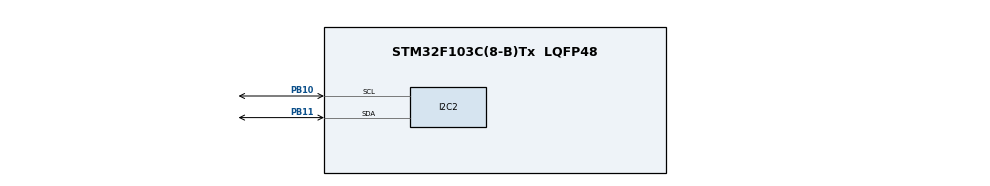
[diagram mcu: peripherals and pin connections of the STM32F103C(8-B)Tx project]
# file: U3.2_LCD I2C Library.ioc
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Mcu.Family=STM32F1
Mcu.Name=STM32F103C(8-B)Tx
Mcu.Package=LQFP48
NVIC.PriorityGroup=NVIC_PRIORITYGROUP_4
PA13.Mode=Serial_Wire
PA13.Signal=SYS_JTMS-SWDIO
PA14.Mode=Serial_Wire
PA14.Signal=SYS_JTCK-SWCLK
PB10.Mode=I2C
PB10.Signal=I2C2_SCL
PB11.Mode=I2C
PB11.Signal=I2C2_SDA
ProjectManager.HeapSize=0x200
ProjectManager.StackSize=0x400
ProjectManager.TargetToolchain=STM32CubeIDE
RCC.APB1Freq_Value=8000000
RCC.APB2Freq_Value=8000000
board=custom

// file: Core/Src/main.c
/* USER CODE BEGIN Header */
/**
  ******************************************************************************
  * @file           : main.c
  * @brief          : Main program body
  ******************************************************************************
  * @attention
  *
  * Copyright (c) 2022 STMicroelectronics.
  * All rights reserved.
  *
  * This software is licensed under terms that can be found in the LICENSE file
  * in the root directory of this software component.
  * If no LICENSE file comes with this software, it is provided AS-IS.
  *
  ******************************************************************************
  */
/* USER CODE END Header */
#include "main.h"

/* USER CODE BEGIN Includes */

#include "LCD_I2C.h"

/* USER CODE END Includes */

 I2C_HandleTypeDef hi2c2;

void SystemClock_Config(void);
static void MX_GPIO_Init(void);
static void MX_I2C2_Init(void);

/* USER CODE BEGIN 0 */
uint8_t arrow_char[] = {
		0b10000,
		0b11000,
		0b11100,
		0b11110,
		0b11100,
		0b11000,
		0b10000,
		0b00000,
};

uint8_t P[] = {
		0b11111,
		0b10001,
		0b10101,
		0b10101,
		0b10001,
		0b10111,
		0b10111,
		0b11111,
};

uint8_t r[] = {
		0b11111,
		0b10001,
		0b10101,
		0b10101,
		0b10001,
		0b10101,
		0b10101,
		0b11111,
};

uint8_t o[] = {
		0b11111,
		0b10001,
		0b10101,
		0b10101,
		0b10101,
		0b10101,
		0b10001,
		0b11111,
};

uint8_t s[] = {
		0b11111,
		0b11111,
		0b11111,
		0b11111,
		0b10001,
		0b11111,
		0b11111,
		0b11111,
};

uint8_t V[] = {
		0b11111,
		0b10101,
		0b10101,
		0b10101,
		0b10101,
		0b10101,
		0b11011,
		0b11111,
};

LCD_I2C_HandleTypeDef hlcd;

/* USER CODE END 0 */

int main(void)
{

  /* MCU Configuration--------------------------------------------------------*/

  /* Reset of all peripherals, Initializes the Flash interface and the Systick. */
  HAL_Init();

  /* Configure the system clock */
  SystemClock_Config();

  /* Initialize all configured peripherals */
  MX_GPIO_Init();
  MX_I2C2_Init();
  /* USER CODE BEGIN 2 */

  LCD_Init(&hlcd, &hi2c2, 20, 4, 0x4E);
  LCD_Backlight(&hlcd);
  HAL_Delay(2000);
//  LCD_Create_Char(&hlcd, 1, arrow_char);
//  LCD_Set_Cursor(&hlcd, 0, 2);
//  LCD_Write_Custom_Char(&hlcd, 1);
//  LCD_Cursor_Blink(&hlcd);

  LCD_Create_Char(&hlcd, 0, P);
  LCD_Set_Cursor(&hlcd, 7, 0);
  LCD_Write_Custom_Char(&hlcd, 0);

  LCD_Create_Char(&hlcd, 1, r);
  LCD_Set_Cursor(&hlcd, 8, 0);
  LCD_Write_Custom_Char(&hlcd, 1);

  LCD_Create_Char(&hlcd, 2, o);
  LCD_Set_Cursor(&hlcd, 9, 0);
  LCD_Write_Custom_Char(&hlcd, 2);

  LCD_Create_Char(&hlcd, 3, s);
  LCD_Set_Cursor(&hlcd, 10, 0);
  LCD_Write_Custom_Char(&hlcd, 3);

  LCD_Create_Char(&hlcd, 4, V);
  LCD_Set_Cursor(&hlcd, 11, 0);
  LCD_Write_Custom_Char(&hlcd, 4);

  LCD_Set_Cursor(&hlcd, 2, 1);
  LCD_Write(&hlcd, "Operator System");

  LCD_Set_Cursor(&hlcd, 5, 2);
  LCD_Write(&hlcd, "Version 1.0");

  HAL_Delay(5000);

  LCD_clear(&hlcd);

  LCD_Set_Cursor(&hlcd, 6, 1);
  LCD_Write(&hlcd, "Welcome!");
  LCD_Set_Cursor(&hlcd, 5, 2);
  LCD_Write(&hlcd, "Loading");

  /* USER CODE END 2 */

  /* Infinite loop */
  while (1)
  {

    /* USER CODE BEGIN 3 */
	  for(int i = 0; i < 3; i++){
		  LCD_Set_Cursor(&hlcd, 12 + i, 2);
		  LCD_Write(&hlcd, ".");
		  HAL_Delay(500);
	  }
	  for(int i = 0; i < 3; i++){
		  LCD_Set_Cursor(&hlcd, 12 + i, 2);
		  LCD_Write(&hlcd, " ");
	  }
	  HAL_Delay(500);

  }
  /* USER CODE END 3 */
}

void SystemClock_Config(void)
{
  RCC_OscInitTypeDef RCC_OscInitStruct = {0};
  RCC_ClkInitTypeDef RCC_ClkInitStruct = {0};

  /** Initializes the RCC Oscillators according to the specified parameters
  * in the RCC_OscInitTypeDef structure.
  */
  RCC_OscInitStruct.OscillatorType = RCC_OSCILLATORTYPE_HSI;
  RCC_OscInitStruct.HSIState = RCC_HSI_ON;
  RCC_OscInitStruct.HSICalibrationValue = RCC_HSICALIBRATION_DEFAULT;
  RCC_OscInitStruct.PLL.PLLState = RCC_PLL_NONE;
  if (HAL_RCC_OscConfig(&RCC_OscInitStruct) != HAL_OK)
  {
    Error_Handler();
  }

  /** Initializes the CPU, AHB and APB buses clocks
  */
  RCC_ClkInitStruct.ClockType = RCC_CLOCKTYPE_HCLK|RCC_CLOCKTYPE_SYSCLK
                              |RCC_CLOCKTYPE_PCLK1|RCC_CLOCKTYPE_PCLK2;
  RCC_ClkInitStruct.SYSCLKSource = RCC_SYSCLKSOURCE_HSI;
  RCC_ClkInitStruct.AHBCLKDivider = RCC_SYSCLK_DIV1;
  RCC_ClkInitStruct.APB1CLKDivider = RCC_HCLK_DIV1;
  RCC_ClkInitStruct.APB2CLKDivider = RCC_HCLK_DIV1;

  if (HAL_RCC_ClockConfig(&RCC_ClkInitStruct, FLASH_LATENCY_0) != HAL_OK)
  {
    Error_Handler();
  }
}

static void MX_I2C2_Init(void)
{

  hi2c2.Instance = I2C2;
  hi2c2.Init.ClockSpeed = 100000;
  hi2c2.Init.DutyCycle = I2C_DUTYCYCLE_2;
  hi2c2.Init.OwnAddress1 = 0;
  hi2c2.Init.AddressingMode = I2C_ADDRESSINGMODE_7BIT;
  hi2c2.Init.DualAddressMode = I2C_DUALADDRESS_DISABLE;
  hi2c2.Init.OwnAddress2 = 0;
  hi2c2.Init.GeneralCallMode = I2C_GENERALCALL_DISABLE;
  hi2c2.Init.NoStretchMode = I2C_NOSTRETCH_DISABLE;
  if (HAL_I2C_Init(&hi2c2) != HAL_OK)
  {
    Error_Handler();
  }

}

static void MX_GPIO_Init(void)
{

  /* GPIO Ports Clock Enable */
  __HAL_RCC_GPIOB_CLK_ENABLE();
  __HAL_RCC_GPIOA_CLK_ENABLE();

}

void Error_Handler(void)
{
  __disable_irq();
  while (1)
  {
  }
}
